# CS__Clock_System_5 register map
Vendor: Texas Instruments
Peripheral module from a debugger description file (folder msp430).
Registers are 16-bit, read-write, reset 0x0 unless marked. A register's access mark holds for its fields unless they carry their own. Offsets are as the file gives them; lines under a group give offsets from that group; [hi:lo] are bit positions; {n}, {i} and the like mark numbered series; 'fields as' and 'values as' point back to an identical list; <NAME> marks a mode.

## CS_Clock_System
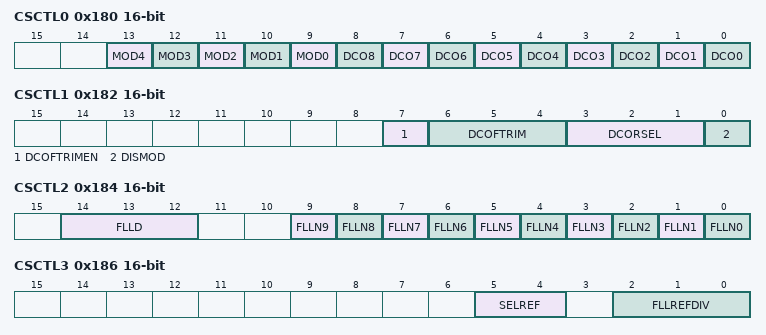
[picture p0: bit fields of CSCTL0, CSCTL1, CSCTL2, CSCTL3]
0x180 CSCTL0 — CS Control Register 0
  [n+9] MOD{n} (n=0..4) — Modulation Bit Counter Bit : {n}
  [n] DCO{n} (n=0..8) — DCO TAP Bit : {n}
0x182 CSCTL1 — CS Control Register 1
  [7] DCOFTRIMEN — DCO frequency trim enable
  [6:4] DCOFTRIM — DCO frequency trim. Bit: 0
    {v}=DCO frequency trim: {v} (v=0..7)
  [3:1] DCORSEL — DCO frequency range select Bit: 0
    {v}=DCO frequency range select: {v} (v=0..7)
  [0] DISMOD — Disable Modulation
0x184 CSCTL2 — CS Control Register 2
  [14:12] FLLD — Loop Divider Bit : 0
    0=Multiply Selected Loop Freq. By 1; 1=Multiply Selected Loop Freq. By 2; 2=Multiply Selected Loop Freq. By 4; 3=Multiply Selected Loop Freq. By 8; 4=Multiply Selected Loop Freq. By 16; 5=Multiply Selected Loop Freq. By 32
  [n] FLLN{n} (n=0..9) — FLL Multipier Bit : {n}
0x186 CSCTL3 — CS Control Register 3
  [5:4] SELREF — FLL Reference Clock Select Bit : 0
    {v}=FLL Reference Clock Select {v} (v=0..3)
  [2:0] FLLREFDIV — Reference Divider Bit : 0
    0=Reference Divider: f(LFCLK)/1; 1=Reference Divider: f(LFCLK)/2; 2=Reference Divider: f(LFCLK)/4; 3=Reference Divider: f(LFCLK)/8; 4=Reference Divider: f(LFCLK)/12; 5=Reference Divider: f(LFCLK)/16; 6=Reference Divider: f(LFCLK)/16; 7=Reference Divider: f(LFCLK)/16
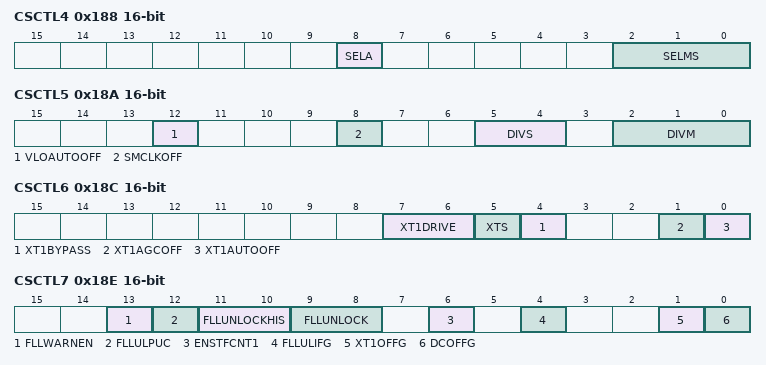
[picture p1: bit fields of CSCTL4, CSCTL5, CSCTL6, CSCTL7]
0x188 CSCTL4 — CS Control Register 4
  [8] SELA — ACLK Source Select Bit: 0
  [2:0] SELMS — MCLK and SMCLK Source Select Bit: 0
    {v}=MCLK and SMCLK Source Select {v} (v=0..7)
0x18A CSCTL5 — CS Control Register 5
  [12] VLOAUTOOFF — VLO automatic off enable
  [8] SMCLKOFF
  [5:4] DIVS — SMCLK Divider Bit: 0
    {v}=SMCLK Source Divider {v} (v=0..3)
  [2:0] DIVM — MCLK Divider Bit: 0
    {v}=MCLK Source Divider {v} (v=0..7)
0x18C CSCTL6 — CS Control Register 6
  [7:6] XT1DRIVE — XT1 Drive Level mode Bit 0
    {v}=XT1 Drive Level mode: {v} (v=0..3)
  [5] XTS — 1: Selects high-freq. oscillator
  [4] XT1BYPASS — XT1 bypass mode : 0: internal 1:sourced from external pin
  [1] XT1AGCOFF — XT1 Automatic Gain Control (AGC) disable
  [0] XT1AUTOOFF — XT1 automatic off enable
0x18E CSCTL7 — CS Control Register 7
  [13] FLLWARNEN — Warning enable
  [12] FLLULPUC — FLL unlock PUC enable
  [11:10] FLLUNLOCKHIS — Unlock history Bit: 0
    {v}=Unlock history: {v} (v=0..3)
  [9:8] FLLUNLOCK — FLL unlock condition Bit: 0
    {v}=FLL unlock condition: {v} (v=0..3)
  [6] ENSTFCNT1 — Enable start counter for XT1
  [4] FLLULIFG — FLL unlock interrupt flag
  [1] XT1OFFG — XT1 Low Frequency Oscillator Fault Flag
  [0] DCOFFG — DCO fault flag
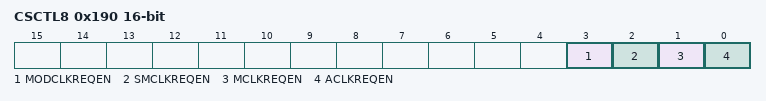
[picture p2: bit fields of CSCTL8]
0x190 CSCTL8 — CS Control Register 8
  [3] MODCLKREQEN — MODOSC Clock Request Enable
  [2] SMCLKREQEN — SMCLK Clock Request Enable
  [1] MCLKREQEN — MCLK Clock Request Enable
  [0] ACLKREQEN — ACLK Clock Request Enable
